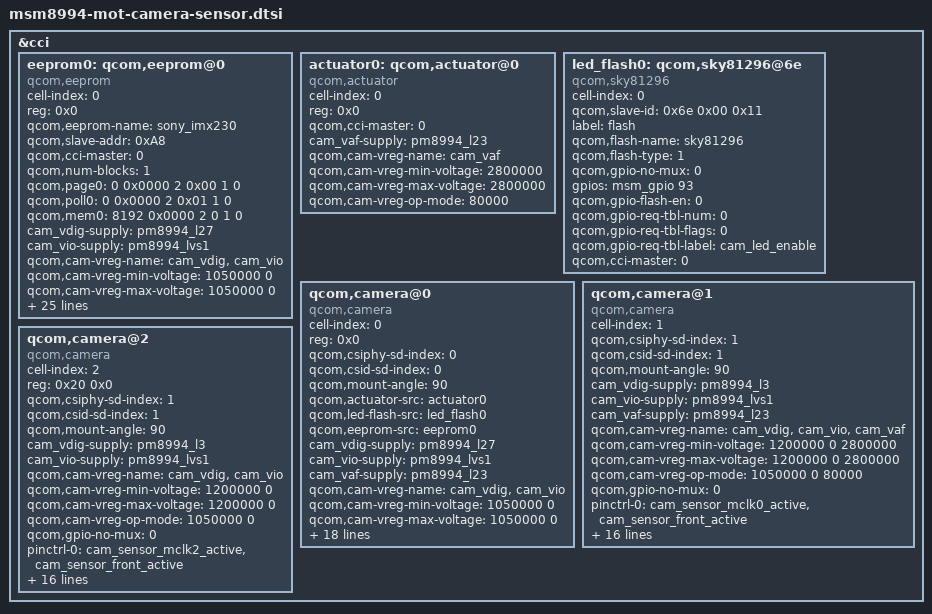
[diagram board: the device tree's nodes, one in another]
/*
 * Copyright (c) 2014, The Linux Foundation. All rights reserved.
 *
 * This program is free software; you can redistribute it and/or modify
 * it under the terms of the GNU General Public License version 2 and
 * only version 2 as published by the Free Software Foundation.
 *
 * This program is distributed in the hope that it will be useful,
 * but WITHOUT ANY WARRANTY; without even the implied warranty of
 * MERCHANTABILITY or FITNESS FOR A PARTICULAR PURPOSE.  See the
 * GNU General Public License for more details.
 */

&cci {

	/* IMX230 EEPROM */
	eeprom0: qcom,eeprom@0 {
		cell-index = <0>;
		reg = <0x0>;
		qcom,eeprom-name = "sony_imx230";
		compatible = "qcom,eeprom";
		qcom,slave-addr = <0xA8>;
		qcom,cci-master = <0>;
		qcom,num-blocks = <1>;
		qcom,page0 = <0 0x0000 2 0x00 1 0>;
		qcom,poll0 = <0 0x0000 2 0x01 1 0>;
		qcom,mem0 = <8192 0x0000 2 0 1 0>;

		cam_vdig-supply = <&pm8994_l27>;
		cam_vio-supply = <&pm8994_lvs1>;
		qcom,cam-vreg-name = "cam_vdig", "cam_vio";
		qcom,cam-vreg-min-voltage = <1050000 0>;
		qcom,cam-vreg-max-voltage = <1050000 0>;
		qcom,cam-vreg-op-mode = <105000 0>;
		qcom,gpio-no-mux = <0>;
		pinctrl-names = "cam_default", "cam_suspend";
		pinctrl-0 = <&cam_sensor_mclk0_active &cam_sensor_rear_active>;
		pinctrl-1 = <&cam_sensor_mclk0_suspend &cam_sensor_rear_suspend>;
		gpios = <&msm_gpio 13 0>,
			<&msm_gpio 30 0>,
			<&msm_gpio 95 0>;
		qcom,gpio-reset = <1>;
		qcom,gpio-vana = <2>;
		qcom,gpio-req-tbl-num = <0 1 2>;
		qcom,gpio-req-tbl-flags = <1 0 0>;
		qcom,gpio-req-tbl-label = "CAMIF_MCLK0",
					  "CAM_RESET0",
					  "CAM_VANA";

		qcom,cam-power-seq-type = "sensor_gpio", "sensor_gpio", "sensor_gpio",
			"sensor_vreg", "sensor_vreg", "sensor_clk", "sensor_gpio";
		qcom,cam-power-seq-val = "sensor_gpio_reset", "sensor_gpio_vana",
			"sensor_gpio_standby", "cam_vio", "cam_vdig", "sensor_cam_mclk",
			"sensor_gpio_reset";
		qcom,cam-power-seq-cfg-val = <0 1 1 1 1 24000000 1>;
		qcom,cam-power-seq-delay = <3 3 3 3 3 5 20>;

		status = "ok";
		clocks = <&clock_mmss clk_mclk0_clk_src>,
				<&clock_mmss clk_camss_mclk0_clk>;
		clock-names = "cam_src_clk", "cam_clk";
	};

	/* IMX230 Actuator */
	actuator0: qcom,actuator@0 {
		cell-index = <0>;
		reg = <0x0>;
		compatible = "qcom,actuator";
		qcom,cci-master = <0>;
		cam_vaf-supply = <&pm8994_l23>;
		qcom,cam-vreg-name = "cam_vaf";
		qcom,cam-vreg-min-voltage = <2800000>;
		qcom,cam-vreg-max-voltage = <2800000>;
		qcom,cam-vreg-op-mode = <80000>;
	};

	/* skywork81296 */
	led_flash0: qcom,sky81296@6e {
		cell-index = <0>;
		qcom,slave-id = <0x6e 0x00 0x11>;
		compatible = "qcom,sky81296";
		label = "flash";
		qcom,flash-name = "sky81296";
		qcom,flash-type = <1>;
		qcom,gpio-no-mux = <0>;
		gpios = <&msm_gpio 93 0>;
		qcom,gpio-flash-en = <0>;
		qcom,gpio-req-tbl-num = <0 >;
		qcom,gpio-req-tbl-flags = <0>;
		qcom,gpio-req-tbl-label = "cam_led_enable";
		qcom,cci-master = <0>;
	};

	/* IMX220 & IMX230 */
	qcom,camera@0 {
		cell-index = <0>;
		compatible = "qcom,camera";
		reg = <0x0>;
		qcom,csiphy-sd-index = <0>;
		qcom,csid-sd-index = <0>;
		qcom,mount-angle = <90>;
		qcom,actuator-src = <&actuator0>;
		qcom,led-flash-src = <&led_flash0>;
		qcom,eeprom-src = <&eeprom0>;
		cam_vdig-supply = <&pm8994_l27>;
		cam_vio-supply = <&pm8994_lvs1>;
		cam_vaf-supply = <&pm8994_l23>;
		qcom,cam-vreg-name = "cam_vdig", "cam_vio";
		qcom,cam-vreg-min-voltage = <1050000 0>;
		qcom,cam-vreg-max-voltage = <1050000 0>;
		qcom,cam-vreg-op-mode = <105000 0>;
		qcom,gpio-no-mux = <0>;
		pinctrl-names = "cam_default", "cam_suspend";
		pinctrl-0 = <&cam_sensor_mclk0_active &cam_sensor_rear_active>;
		pinctrl-1 = <&cam_sensor_mclk0_suspend &cam_sensor_rear_suspend>;
		gpios = <&msm_gpio 13 0>,
			<&msm_gpio 30 0>,
			<&msm_gpio 95 0>;
		qcom,gpio-reset = <1>;
		qcom,gpio-vana = <2>;
		qcom,gpio-req-tbl-num = <0 1 2>;
		qcom,gpio-req-tbl-flags = <1 0 0>;
		qcom,gpio-req-tbl-label = "CAMIF_MCLK0",
					  "CAM_RESET0",
					  "CAM_VANA";
		qcom,sensor-position = <0>;
		qcom,sensor-mode = <0>;
		qcom,cci-master = <0>;
		status = "ok";
		clocks = <&clock_mmss clk_mclk0_clk_src>,
				<&clock_mmss clk_camss_mclk0_clk>;
		clock-names = "cam_src_clk", "cam_clk";
	};

	/* ov5693 */
	qcom,camera@1 {
		cell-index = <1>;
		compatible = "qcom,camera";
		qcom,csiphy-sd-index = <1>;
		qcom,csid-sd-index = <1>;
		qcom,mount-angle = <90>;
		cam_vdig-supply = <&pm8994_l3>;
		cam_vio-supply = <&pm8994_lvs1>;
		cam_vaf-supply = <&pm8994_l23>;
		qcom,cam-vreg-name = "cam_vdig", "cam_vio", "cam_vaf";
		qcom,cam-vreg-min-voltage = <1200000 0 2800000>;
		qcom,cam-vreg-max-voltage = <1200000 0 2800000>;
		qcom,cam-vreg-op-mode = <1050000 0 80000>;
		qcom,gpio-no-mux = <0>;
		pinctrl-names = "cam_default", "cam_suspend";
		pinctrl-0 = <&cam_sensor_mclk0_active &cam_sensor_front_active>;
		pinctrl-1 = <&cam_sensor_mclk0_suspend &cam_sensor_front_suspend>;
		gpios = <&msm_gpio 13 0>,
			<&msm_gpio 133 0>,
			<&msm_gpio 132 0>,
			<&msm_gpio 95 0>;
		qcom,gpio-reset = <1>;
		qcom,gpio-standby = <2>;
		qcom,gpio-vana = <3>;
		qcom,gpio-req-tbl-num = <0 1 2 3>;
		qcom,gpio-req-tbl-flags = <1 0 0 0>;
		qcom,gpio-req-tbl-label = "CAMIF_MCLK1",
					  "CAM_RESET1",
					  "CAM_STANDBY1",
					  "CAM_VANA";
		qcom,sensor-position = <1>;
		qcom,sensor-mode = <0>;
		qcom,cci-master = <0>;
		status = "ok";
		clocks = <&clock_mmss clk_mclk0_clk_src>,
				<&clock_mmss clk_camss_mclk0_clk>;
		clock-names = "cam_src_clk", "cam_clk";
	};

	/* ov5693 */
	qcom,camera@1 {
		cell-index = <1>;
		compatible = "qcom,camera";
		qcom,csiphy-sd-index = <1>;
		qcom,csid-sd-index = <1>;
		qcom,mount-angle = <90>;
		cam_vdig-supply = <&pm8994_l3>;
		cam_vio-supply = <&pm8994_lvs1>;
		cam_vaf-supply = <&pm8994_l23>;
		qcom,cam-vreg-name = "cam_vdig", "cam_vio", "cam_vaf";
		qcom,cam-vreg-min-voltage = <1200000 0 2800000>;
		qcom,cam-vreg-max-voltage = <1200000 0 2800000>;
		qcom,cam-vreg-op-mode = <1050000 0 80000>;
		qcom,gpio-no-mux = <0>;
		pinctrl-names = "cam_default", "cam_suspend";
		pinctrl-0 = <&cam_sensor_mclk0_active &cam_sensor_front_active>;
		pinctrl-1 = <&cam_sensor_mclk0_suspend &cam_sensor_front_suspend>;
		gpios = <&msm_gpio 13 0>,
			<&msm_gpio 133 0>,
			<&msm_gpio 132 0>,
			<&msm_gpio 95 0>;
		qcom,gpio-reset = <1>;
		qcom,gpio-standby = <2>;
		qcom,gpio-vana = <3>;
		qcom,gpio-req-tbl-num = <0 1 2 3>;
		qcom,gpio-req-tbl-flags = <1 0 0 0>;
		qcom,gpio-req-tbl-label = "CAMIF_MCLK1",
					  "CAM_RESET1",
					  "CAM_STANDBY1",
					  "CAM_VANA";
		qcom,sensor-position = <1>;
		qcom,sensor-mode = <0>;
		qcom,cci-master = <0>;
		status = "ok";
		clocks = <&clock_mmss clk_mclk0_clk_src>,
				<&clock_mmss clk_camss_mclk0_clk>;
		clock-names = "cam_src_clk", "cam_clk";
	};

	/* s5k5e2ya */
	qcom,camera@2 {
		cell-index = <2>;
		compatible = "qcom,camera";
		reg = <0x20 0x0>;
		qcom,csiphy-sd-index = <1>;
		qcom,csid-sd-index = <1>;
		qcom,mount-angle = <90>;
		cam_vdig-supply = <&pm8994_l3>;
		cam_vio-supply = <&pm8994_lvs1>;
		qcom,cam-vreg-name = "cam_vdig", "cam_vio";
		qcom,cam-vreg-min-voltage = <1200000 0>;
		qcom,cam-vreg-max-voltage = <1200000 0>;
		qcom,cam-vreg-op-mode = <1050000 0>;
		qcom,gpio-no-mux = <0>;
		pinctrl-names = "cam_default", "cam_suspend";
		pinctrl-0 = <&cam_sensor_mclk2_active &cam_sensor_front_active>;
		pinctrl-1 = <&cam_sensor_mclk2_suspend &cam_sensor_front_suspend>;
		gpios = <&msm_gpio 15 0>,
			<&msm_gpio 133 0>,
			<&msm_gpio 132 0>,
			<&msm_gpio 95 0>;
		qcom,gpio-reset = <1>;
		qcom,gpio-standby = <2>;
		qcom,gpio-vana = <3>;
		qcom,gpio-req-tbl-num = <0 1 2 3>;
		qcom,gpio-req-tbl-flags = <1 0 0 0>;
		qcom,gpio-req-tbl-label = "CAMIF_MCLK1",
					  "CAM_RESET1",
					  "CAM_STANDBY1",
					  "CAM_VANA";
		qcom,sensor-position = <1>;
		qcom,sensor-mode = <0>;
		qcom,cci-master = <0>;
		status = "ok";
		clocks = <&clock_mmss clk_mclk2_clk_src>,
				<&clock_mmss clk_camss_mclk2_clk>;
		clock-names = "cam_src_clk", "cam_clk";
	};
};
